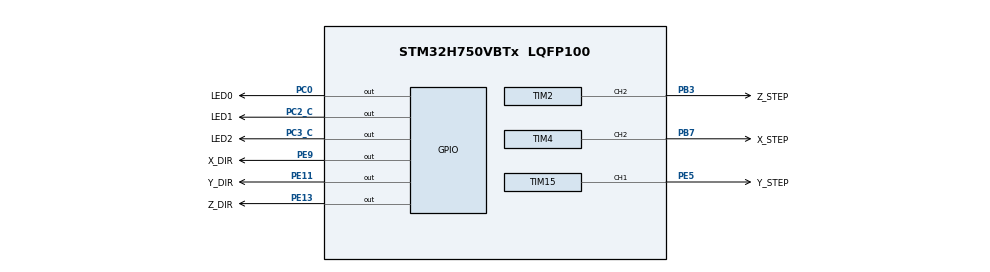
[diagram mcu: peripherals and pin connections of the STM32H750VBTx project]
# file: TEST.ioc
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Mcu.Family=STM32H7
Mcu.Name=STM32H750VBTx
Mcu.Package=LQFP100
NVIC.PriorityGroup=NVIC_PRIORITYGROUP_4
NVIC.TIM15_IRQn=true\:1\:0\:true\:false\:true\:true\:true
NVIC.TIM2_IRQn=true\:1\:0\:true\:false\:true\:true\:true
NVIC.TIM4_IRQn=true\:1\:0\:true\:false\:true\:true\:true
PB3\ (JTDO/TRACESWO).GPIO_Label=Z_STEP
PB3\ (JTDO/TRACESWO).GPIO_PuPd=GPIO_PULLUP
PB3\ (JTDO/TRACESWO).GPIO_Speed=GPIO_SPEED_FREQ_HIGH
PB3\ (JTDO/TRACESWO).Signal=S_TIM2_CH2
PB7.GPIO_FM7=__NULL
PB7.GPIO_Label=X_STEP
PB7.GPIO_PuPd=GPIO_PULLUP
PB7.GPIO_Speed=GPIO_SPEED_FREQ_HIGH
PB7.Signal=S_TIM4_CH2
PC0.GPIO_Label=LED0
PC0.Signal=GPIO_Output
PC2_C.GPIO_Label=LED1
PC2_C.Signal=GPIO_Output
PC3_C.GPIO_Label=LED2
PC3_C.Signal=GPIO_Output
PE11.GPIO_Label=Y_DIR
PE11.GPIO_PuPd=GPIO_PULLUP
PE11.GPIO_Speed=GPIO_SPEED_FREQ_HIGH
PE11.Signal=GPIO_Output
PE13.GPIO_Label=Z_DIR
PE13.GPIO_PuPd=GPIO_PULLUP
PE13.GPIO_Speed=GPIO_SPEED_FREQ_HIGH
PE13.Signal=GPIO_Output
PE5.GPIO_Label=Y_STEP
PE5.GPIO_PuPd=GPIO_PULLUP
PE5.GPIO_Speed=GPIO_SPEED_FREQ_HIGH
PE5.Signal=S_TIM15_CH1
PE9.GPIO_Label=X_DIR
PE9.GPIO_PuPd=GPIO_PULLUP
PE9.GPIO_Speed=GPIO_SPEED_FREQ_HIGH
PE9.Signal=GPIO_Output
ProjectManager.HeapSize=0x200
ProjectManager.StackSize=0x400
ProjectManager.TargetToolchain=MDK-ARM V5.27
RCC.ADCFreq_Value=129000000
RCC.APB1Freq_Value=60000000
RCC.APB2Freq_Value=60000000
RCC.APB3Freq_Value=60000000
RCC.APB4Freq_Value=60000000
RCC.CortexFreq_Value=120000000
RCC.DIVM1=4
RCC.DIVN1=15
RCC.HCLKFreq_Value=60000000
RCC.HPRE=RCC_HCLK_DIV2
RCC.PLL2FRACN=0
RCC.PLL3FRACN=0
RCC.PLLFRACN=0
RCC.SYSCLKFreq_VALUE=120000000
RCC.SYSCLKSource=RCC_SYSCLKSOURCE_PLLCLK
RCC.USBFreq_Value=120000000
SH.S_TIM15_CH1.0=TIM15_CH1,PWM Generation1 CH1
SH.S_TIM2_CH2.0=TIM2_CH2,PWM Generation2 CH2
SH.S_TIM4_CH2.0=TIM4_CH2,PWM Generation2 CH2
TIM15.AutoReloadPreload=TIM_AUTORELOAD_PRELOAD_ENABLE
TIM15.Channel-PWM\ Generation1\ CH1=TIM_CHANNEL_1
TIM15.ClockDivision=TIM_CLOCKDIVISION_DIV4
TIM15.OC1Preload_PWM=DISABLE
TIM15.Period=100-1
TIM15.Prescaler=60-1
TIM15.Pulse-PWM\ Generation1\ CH1=50
TIM2.AutoReloadPreload=TIM_AUTORELOAD_PRELOAD_ENABLE
TIM2.Channel-PWM\ Generation2\ CH2=TIM_CHANNEL_2
TIM2.OC2Preload_PWM=DISABLE
TIM2.Period=100-1
TIM2.Prescaler=60-1
TIM2.Pulse-PWM\ Generation2\ CH2=50
TIM4.AutoReloadPreload=TIM_AUTORELOAD_PRELOAD_ENABLE
TIM4.Channel-PWM\ Generation2\ CH2=TIM_CHANNEL_2
TIM4.ClockDivision=TIM_CLOCKDIVISION_DIV4
TIM4.OC2Preload_PWM=DISABLE
TIM4.Period=100-1
TIM4.Prescaler=60-1
TIM4.Pulse-PWM\ Generation2\ CH2=50
board=custom

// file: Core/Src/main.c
/* USER CODE BEGIN Header */
/**
  ******************************************************************************
  * @file           : main.c
  * @brief          : Main program body
  ******************************************************************************
  * @attention
  *
  * <h2><center>&copy; Copyright (c) 2022 STMicroelectronics.
  * All rights reserved.</center></h2>
  *
  * This software component is licensed by ST under BSD 3-Clause license,
  * the "License"; You may not use this file except in compliance with the
  * License. You may obtain a copy of the License at:
  *                        opensource.org/licenses/BSD-3-Clause
  *
  ******************************************************************************
  */
/* USER CODE END Header */
#include "main.h"
#include "tim.h"
#include "gpio.h"

/* USER CODE BEGIN Includes */
#include "draw.h"
#include "testdata.h"
/* USER CODE END Includes */

void SystemClock_Config(void);

int main(void)
{

  /* MCU Configuration--------------------------------------------------------*/

  /* Reset of all peripherals, Initializes the Flash interface and the Systick. */
  HAL_Init();

  /* Configure the system clock */
  SystemClock_Config();

  /* Initialize all configured peripherals */
  MX_GPIO_Init();
  MX_TIM4_Init();
  MX_TIM2_Init();
  MX_TIM15_Init();
  /* USER CODE BEGIN 2 */
	HAL_TIM_Base_Init(&htim4);

  /* USER CODE END 2 */

  /* Infinite loop */
  /* USER CODE BEGIN WHILE */

	drawbitimg(gImage_4);
  while (1)
  {
			HAL_Delay(1000);

//			drawrow(0,100);
//			HAL_Delay(100);
//			drawrow(1,100);
//			HAL_Delay(100);

//			for(int i = 0; i < 10; i++)
//			{
//				drawrow(1,100);
//				HAL_Delay(100);
//				drawcol(1,1);
//				HAL_Delay(100);
//				drawrow(0,100);
//				HAL_Delay(100);
//				drawcol(1,1);
//				HAL_Delay(100);
//			}

//			drawline(test);
//			drawrow(0,320);
//			drawbitline(gImage_3);
//			drawbitpage(gImage_3);

    /* USER CODE END WHILE */

  }
}

void SystemClock_Config(void)
{
  RCC_OscInitTypeDef RCC_OscInitStruct = {0};
  RCC_ClkInitTypeDef RCC_ClkInitStruct = {0};

  /** Supply configuration update enable
  */
  HAL_PWREx_ConfigSupply(PWR_LDO_SUPPLY);
  /** Configure the main internal regulator output voltage
  */
  __HAL_PWR_VOLTAGESCALING_CONFIG(PWR_REGULATOR_VOLTAGE_SCALE3);

  while(!__HAL_PWR_GET_FLAG(PWR_FLAG_VOSRDY)) {}
  /** Initializes the RCC Oscillators according to the specified parameters
  * in the RCC_OscInitTypeDef structure.
  */
  RCC_OscInitStruct.OscillatorType = RCC_OSCILLATORTYPE_HSI;
  RCC_OscInitStruct.HSIState = RCC_HSI_DIV1;
  RCC_OscInitStruct.HSICalibrationValue = RCC_HSICALIBRATION_DEFAULT;
  RCC_OscInitStruct.PLL.PLLState = RCC_PLL_ON;
  RCC_OscInitStruct.PLL.PLLSource = RCC_PLLSOURCE_HSI;
  RCC_OscInitStruct.PLL.PLLM = 4;
  RCC_OscInitStruct.PLL.PLLN = 15;
  RCC_OscInitStruct.PLL.PLLP = 2;
  RCC_OscInitStruct.PLL.PLLQ = 2;
  RCC_OscInitStruct.PLL.PLLR = 2;
  RCC_OscInitStruct.PLL.PLLRGE = RCC_PLL1VCIRANGE_3;
  RCC_OscInitStruct.PLL.PLLVCOSEL = RCC_PLL1VCOWIDE;
  RCC_OscInitStruct.PLL.PLLFRACN = 0;
  if (HAL_RCC_OscConfig(&RCC_OscInitStruct) != HAL_OK)
  {
    Error_Handler();
  }
  /** Initializes the CPU, AHB and APB buses clocks
  */
  RCC_ClkInitStruct.ClockType = RCC_CLOCKTYPE_HCLK|RCC_CLOCKTYPE_SYSCLK
                              |RCC_CLOCKTYPE_PCLK1|RCC_CLOCKTYPE_PCLK2
                              |RCC_CLOCKTYPE_D3PCLK1|RCC_CLOCKTYPE_D1PCLK1;
  RCC_ClkInitStruct.SYSCLKSource = RCC_SYSCLKSOURCE_PLLCLK;
  RCC_ClkInitStruct.SYSCLKDivider = RCC_SYSCLK_DIV1;
  RCC_ClkInitStruct.AHBCLKDivider = RCC_HCLK_DIV2;
  RCC_ClkInitStruct.APB3CLKDivider = RCC_APB3_DIV1;
  RCC_ClkInitStruct.APB1CLKDivider = RCC_APB1_DIV1;
  RCC_ClkInitStruct.APB2CLKDivider = RCC_APB2_DIV1;
  RCC_ClkInitStruct.APB4CLKDivider = RCC_APB4_DIV1;

  if (HAL_RCC_ClockConfig(&RCC_ClkInitStruct, FLASH_LATENCY_1) != HAL_OK)
  {
    Error_Handler();
  }
}

void Error_Handler(void)
{
  __disable_irq();
  while (1)
  {
  }
}

/************************ (C) COPYRIGHT STMicroelectronics *****END OF FILE****/
